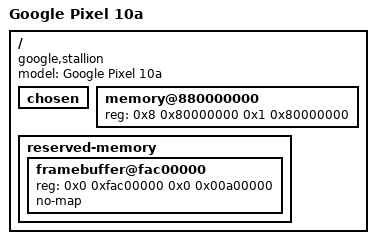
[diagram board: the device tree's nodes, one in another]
/dts-v1/;
/include/ "zumapro.dtsi"

/*
 * Google Pixel 10a (stallion).
 *
 * The chip's cores, timer and interrupt controller come from the included
 * file. What is here is this phone's own: how much memory the kernel may
 * have, and the buffer the panel is read from.
 */

/ {
    model = "Google Pixel 10a";
    compatible = "google,stallion", "google,zumapro";

    chosen {
    };

    /*
     * One contiguous range, and deliberately not all of the memory.
     *
     * This phone has 8 GiB in four banks: 2 GiB at 0x80000000 and three more
     * at 0x880000000, 0x900000000 and 0x980000000. The kernel maps whatever
     * it is given as ordinary cacheable memory, so the range may hold no
     * vendor carve-out. Every reservation on this phone, the bootloader's own
     * region, the debug buffers and the framebuffer among them, sits in the
     * low bank. The three high banks are adjacent and clean, so they are
     * handed over as one 6 GiB block and the low bank is left alone.
     */
    memory@880000000 {
        device_type = "memory";
        reg = <0x8 0x80000000 0x1 0x80000000>;
        status = "okay";
    };

    /*
     * The buffer the panel is scanned out of. Our firmware draws here and the
     * display controller fetches it continuously, so nothing may reuse it.
     * The kernel learns the geometry from the graphics protocol at handover,
     * not from here.
     */
    reserved-memory {
        #address-cells = <2>;
        #size-cells = <2>;
        ranges;

        framebuffer@fac00000 {
            reg = <0x0 0xfac00000 0x0 0x00a00000>;
            no-map;
        };
    };
};
